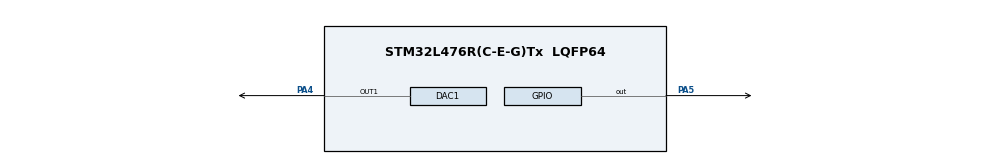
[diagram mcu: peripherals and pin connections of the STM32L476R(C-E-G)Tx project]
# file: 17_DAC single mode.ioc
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DAC1.DAC_Trigger-DAC_OUT1=DAC_TRIGGER_NONE
Mcu.Family=STM32L4
Mcu.Name=STM32L476R(C-E-G)Tx
Mcu.Package=LQFP64
NVIC.PriorityGroup=NVIC_PRIORITYGROUP_4
PA13\ (JTMS-SWDIO).Mode=Serial_Wire
PA13\ (JTMS-SWDIO).Signal=SYS_JTMS-SWDIO
PA14\ (JTCK-SWCLK).Mode=Serial_Wire
PA14\ (JTCK-SWCLK).Signal=SYS_JTCK-SWCLK
PA4.Signal=COMP_DAC11_group
PA5.Signal=GPIO_Output
ProjectManager.HeapSize=0x200
ProjectManager.StackSize=0x400
ProjectManager.TargetToolchain=STM32CubeIDE
RCC.HSE_VALUE=8000000
RCC.HSI_VALUE=16000000
RCC.LSE_VALUE=32768
RCC.MSI_VALUE=4000000
RCC.VCOOutputFreq_Value=32000000
SH.COMP_DAC11_group.0=DAC1_OUT1,DAC_OUT1
board=custom

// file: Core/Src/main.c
/* USER CODE BEGIN Header */
/**
  ******************************************************************************
  * @file           : main.c
  * @brief          : Main program body
  ******************************************************************************
  * @attention
  *
  * Copyright (c) 2023 STMicroelectronics.
  * All rights reserved.
  *
  * This software is licensed under terms that can be found in the LICENSE file
  * in the root directory of this software component.
  * If no LICENSE file comes with this software, it is provided AS-IS.
  *
  ******************************************************************************
  */
/* USER CODE END Header */
#include "main.h"

DAC_HandleTypeDef hdac1;

void SystemClock_Config(void);
static void MX_GPIO_Init(void);
static void MX_DAC1_Init(void);

/* USER CODE BEGIN 0 */
 uint32_t DOR_val = 0 ;

/* USER CODE END 0 */

int main(void)
{
  /* USER CODE BEGIN 1 */
  uint32_t DAC_OUT[4] = {0, 1241, 2482, 3723};
  uint8_t i = 0;

  /* USER CODE END 1 */

  /* MCU Configuration--------------------------------------------------------*/

  /* Reset of all peripherals, Initializes the Flash interface and the Systick. */
  HAL_Init();

  /* Configure the system clock */
  SystemClock_Config();

  /* Initialize all configured peripherals */
  MX_GPIO_Init();
  MX_DAC1_Init();

  /* Infinite loop */
  while (1)
  {

    /* USER CODE BEGIN 3 */
	DAC1->DHR12R1 = DAC_OUT[i]; // or DAC_OUT[i++]
	DOR_val = DAC1->DOR1; // The DOR_val is used to view in live expression the data been transfered to the DOR1 register
	i++;// and remove this
    if(i == 4)
    {
        i = 0;
    }
    HAL_GPIO_TogglePin(GPIOA, GPIO_PIN_5);
    HAL_Delay(1000);
  }
  /* USER CODE END 3 */
}

void SystemClock_Config(void)
{
  RCC_OscInitTypeDef RCC_OscInitStruct = {0};
  RCC_ClkInitTypeDef RCC_ClkInitStruct = {0};

  /** Configure the main internal regulator output voltage
  */
  if (HAL_PWREx_ControlVoltageScaling(PWR_REGULATOR_VOLTAGE_SCALE1) != HAL_OK)
  {
    Error_Handler();
  }

  /** Initializes the RCC Oscillators according to the specified parameters
  * in the RCC_OscInitTypeDef structure.
  */
  RCC_OscInitStruct.OscillatorType = RCC_OSCILLATORTYPE_MSI;
  RCC_OscInitStruct.MSIState = RCC_MSI_ON;
  RCC_OscInitStruct.MSICalibrationValue = 0;
  RCC_OscInitStruct.MSIClockRange = RCC_MSIRANGE_6;
  RCC_OscInitStruct.PLL.PLLState = RCC_PLL_NONE;
  if (HAL_RCC_OscConfig(&RCC_OscInitStruct) != HAL_OK)
  {
    Error_Handler();
  }

  /** Initializes the CPU, AHB and APB buses clocks
  */
  RCC_ClkInitStruct.ClockType = RCC_CLOCKTYPE_HCLK|RCC_CLOCKTYPE_SYSCLK
                              |RCC_CLOCKTYPE_PCLK1|RCC_CLOCKTYPE_PCLK2;
  RCC_ClkInitStruct.SYSCLKSource = RCC_SYSCLKSOURCE_MSI;
  RCC_ClkInitStruct.AHBCLKDivider = RCC_SYSCLK_DIV1;
  RCC_ClkInitStruct.APB1CLKDivider = RCC_HCLK_DIV1;
  RCC_ClkInitStruct.APB2CLKDivider = RCC_HCLK_DIV1;

  if (HAL_RCC_ClockConfig(&RCC_ClkInitStruct, FLASH_LATENCY_0) != HAL_OK)
  {
    Error_Handler();
  }
}

static void MX_DAC1_Init(void)
{

  DAC_ChannelConfTypeDef sConfig = {0};

  /** DAC Initialization
  */
  hdac1.Instance = DAC1;
  if (HAL_DAC_Init(&hdac1) != HAL_OK)
  {
    Error_Handler();
  }

  /** DAC channel OUT1 config
  */
  sConfig.DAC_SampleAndHold = DAC_SAMPLEANDHOLD_DISABLE;
  sConfig.DAC_Trigger = DAC_TRIGGER_NONE;
  sConfig.DAC_OutputBuffer = DAC_OUTPUTBUFFER_ENABLE;
  sConfig.DAC_ConnectOnChipPeripheral = DAC_CHIPCONNECT_DISABLE;
  sConfig.DAC_UserTrimming = DAC_TRIMMING_FACTORY;
  if (HAL_DAC_ConfigChannel(&hdac1, &sConfig, DAC_CHANNEL_1) != HAL_OK)
  {
    Error_Handler();
  }

}

static void MX_GPIO_Init(void)
{
  GPIO_InitTypeDef GPIO_InitStruct = {0};

  /* GPIO Ports Clock Enable */
  __HAL_RCC_GPIOA_CLK_ENABLE();

  /*Configure GPIO pin Output Level */
  HAL_GPIO_WritePin(GPIOA, GPIO_PIN_5, GPIO_PIN_RESET);

  /*Configure GPIO pin : PA5 */
  GPIO_InitStruct.Pin = GPIO_PIN_5;
  GPIO_InitStruct.Mode = GPIO_MODE_OUTPUT_PP;
  GPIO_InitStruct.Pull = GPIO_NOPULL;
  GPIO_InitStruct.Speed = GPIO_SPEED_FREQ_LOW;
  HAL_GPIO_Init(GPIOA, &GPIO_InitStruct);

}

void Error_Handler(void)
{
  __disable_irq();
  while (1)
  {
  }
}
